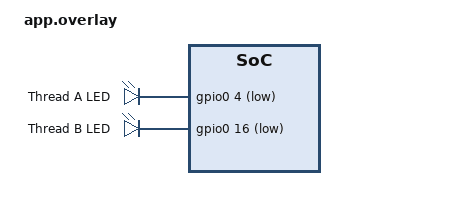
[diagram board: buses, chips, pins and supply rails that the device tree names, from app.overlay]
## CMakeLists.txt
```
cmake_minimum_required(VERSION 3.20.0)
#set(BOARD esp32_devkitc/esp32/procpu)#set(BOARD_FLASH_RUNNER openocd)
find_package(Zephyr REQUIRED HINTS $ENV{ZEPHYR_BASE})
project(blinky_led)

target_sources(app PRIVATE src/main.c)
target_sources(app PRIVATE src/threadA.c)
target_sources(app PRIVATE src/threadB.c)
```

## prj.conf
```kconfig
CONFIG_ESP32_USE_UNSUPPORTED_REVISION=y
CONFIG_LOG=y
CONFIG_NETWORKING=y
CONFIG_WIFI=y
CONFIG_WIFI_ESP32=y
CONFIG_NET_L2_WIFI_MGMT=y
CONFIG_NET_MGMT=y
CONFIG_NET_MGMT_EVENT=y
CONFIG_NET_MGMT_EVENT_INFO=y

# Event yöneticisinin logları (debug için açık kalabilir)

# Bellek Ayarları (Olmazsa olmaz)
CONFIG_NET_MGMT_EVENT_STACK_SIZE=4096
CONFIG_SYSTEM_WORKQUEUE_STACK_SIZE=2048
CONFIG_MAIN_STACK_SIZE=4096
```

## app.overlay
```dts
/ {
	aliases {
		led0 = &user_led_0;
		led1 = &user_led_1;
	};

	leds {
		compatible = "gpio-leds";
		user_led_0: led_0 {
			gpios = <&gpio0 4 GPIO_ACTIVE_LOW>;
			label = "Thread A LED";
		};
		user_led_1: led_1 {
			gpios = <&gpio0 16 GPIO_ACTIVE_LOW>;
			label = "Thread B LED";
		};
	};
};
```

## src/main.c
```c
#include <zephyr/kernel.h>
#include <zephyr/net/net_if.h>
#include <zephyr/net/net_mgmt.h>
#include <zephyr/net/wifi_mgmt.h>
#include <string.h>

static void scan_result_handler(struct net_mgmt_event_callback *cb,
                                uint32_t mgmt_event, struct net_if *iface)
{
    const struct wifi_scan_result *res = (const struct wifi_scan_result *)cb->info;
    
    if (res)
	{

        char ssid_str[33] = {0};
        uint8_t len = (res->ssid_length <= 32) ? res->ssid_length : 32;
        memcpy(ssid_str, res->ssid, len);

        // Dogrudan donanim uzerinden (UART) ekrana bas
        printk("[NODE DETECTED] SSID: %-20s | RSSI: %4d dBm | Channel: %2d\n", 
               ssid_str, res->rssi, res->channel);
    }
}


static void scan_done_handler(struct net_mgmt_event_callback *cb,
                              uint32_t mgmt_event, struct net_if *iface)
{
    printk("\n--- Scan Completed ---\n\n");
}

static struct net_mgmt_event_callback scan_res_cb;
static struct net_mgmt_event_callback scan_done_cb;

int main(void)
{
    struct net_if *iface = net_if_get_default();

    net_mgmt_init_event_callback(&scan_res_cb, (net_mgmt_event_handler_t)scan_result_handler, NET_EVENT_WIFI_SCAN_RESULT);
    net_mgmt_add_event_callback(&scan_res_cb);

    net_mgmt_init_event_callback(&scan_done_cb, (net_mgmt_event_handler_t)scan_done_handler, NET_EVENT_WIFI_SCAN_DONE);
    net_mgmt_add_event_callback(&scan_done_cb);

    printk("\nWating for Wi-Fi interface to be ready...\n");
    k_sleep(K_SECONDS(2)); 
    net_if_up(iface);
    k_sleep(K_MSEC(500)); 

    printk("\nScanning for Wi-Fi networks...\n");

    if (net_mgmt(NET_REQUEST_WIFI_SCAN, iface, NULL, 0)) {
        printk("Failed to start scan!\n");
        return -1;
    }

    while (1) {
        k_sleep(K_SECONDS(10));
    }

    return 0;
}
```

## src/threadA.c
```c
#include <zephyr/drivers/gpio.h>


#define LED0_NODE DT_ALIAS(led0)
static const struct gpio_dt_spec led0 = GPIO_DT_SPEC_GET(LED0_NODE, gpios);


void Thread_A(void *dummy1, void *dummy2, void *dummy3)
{
        if (!gpio_is_ready_dt(&led0)) 
        {
    }

    gpio_pin_configure_dt(&led0, GPIO_OUTPUT_ACTIVE);
    
    while(1)
    {
        gpio_pin_toggle_dt(&led0);
        printk("Thread A running!\n");

        k_msleep(1000); // 500ms wait (Blink speed)
    }
    
}
```

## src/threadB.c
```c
#include <zephyr/drivers/gpio.h>


#define LED1_NODE DT_ALIAS(led1)

static const struct gpio_dt_spec led1 = GPIO_DT_SPEC_GET(LED1_NODE, gpios);


void Thread_B(void *dummy1, void *dummy2, void *dummy3)
{
        if (!gpio_is_ready_dt(&led1)) 
        {
    }

    gpio_pin_configure_dt(&led1, GPIO_OUTPUT_ACTIVE);
    
    while(1)
    {
        gpio_pin_toggle_dt(&led1);
        printk("Thread B running\n");

        k_msleep(500);
    }

}
```
